# ccg6df_cfp register map
Vendor: Infineon Technologies; Series: CCG6DF_CFP; File version: 1.0
CPU: CM0PLUS r0p1, little endian, MPU, no FPU, VTOR, 2 interrupt priority bits, 20 interrupts
Registers are 32-bit, read-write, reset 0x0 unless marked. A register's access mark holds for its fields unless they carry their own. Offsets are from the block's base; [hi:lo] are bit positions.

## CRYPTOLITE
Base 0x400C0000
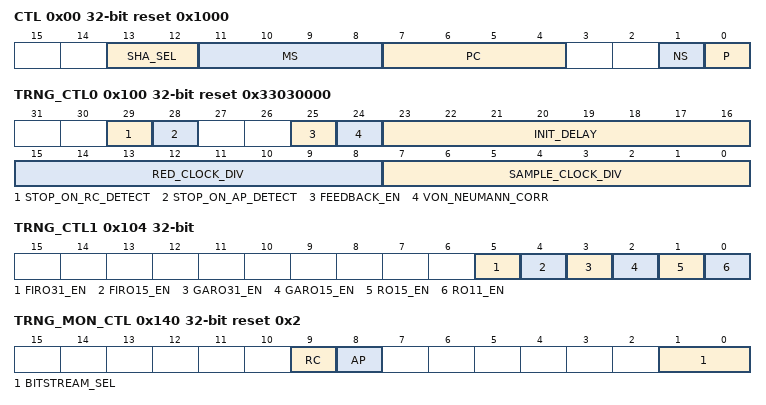
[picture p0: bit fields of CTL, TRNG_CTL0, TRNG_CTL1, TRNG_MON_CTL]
0x00 CTL reset 0x1000 (reset mask 0x3F00) — Control
  [13:12] SHA_SEL — Selects SHA function for use. 0x0: SHA operation is disabled. 0x1: SHA-256 operation is enabled. 0x2: SHA-384 operation is enabled. 0x3: SHA-512 operation is enabled.
  [11:8] MS ro — Master identifier of the cryptography IP. This is a design time configurable parameter.
  [7:4] PC ro — Protection context. This field is set with the protection context of the transaction that writes any (including possible memory holes in the IP aperture) of the CRYPTO component registers; i.e. the context is inherited from the write transaction and not specified by the transaction write data. All CRYPTO component master transactions use the PC field for the protection context.
  [1] NS ro — Secure/on-secure access control: '0': secure. '1': non-secure. This field is set with the secure/non-secure access control of the transaction that writes any (including possible memory holes in the IP aperture) of the CRYPTO component registers; i.e. the access control is inherited from the write transaction and not specified by the transaction write data. All CRYPTO component master transactions use the NS field for the secure/non-secure access control ('hprot[4]').
  [0] P ro — User/privileged access control: '0': user mode. '1': privileged mode. This field is set with the user/privileged access control of the transaction that writes any (including possible memory holes in the IP aperture) of the CRYPTO component registers; i.e. the access control is inherited from the write transaction and not specified by the transaction write data. All CRYPTO component master transactions use the P field for the user/privileged access control ('hprot[1]').
0x04 STATUS ro
  [0] BUSY — Busy indication: '0': IP not busy. '1': IP busy (AES, SHA or VU functionality (TRNG functionality NOT included)).
0x10 ECC_CTL — ECC control
  [3] CHECK_EN — ECC checking enable: '0': Disabled. No ECC checking, no fault reporting. '1': Enabled. ECC checking is performed for the AHB-Lite master interface incoming read data and for the AHB-Lite slave interface incoming write data (for MMIO writes). For the AHB-Lite master interface, error correction is NOT performed (even NOT for theoratically correctable ECC errors). Therefore, an ECC error is always non-correctable. ECC errors do not generate a bus error. This decision is made as error corection and bus error generation would end up in a critical timing path. For the AHB-Lite slave interface, error correction is performed for correctable ECC errors. An ECC error is either correctable or non-correctable. Two fault signal interfaces are supported for correctable and non-correctable ECC errors.
0x40 AES_DESCR reset not defined — AES descriptor pointer
  [31:2] PTR — AES descriptor pointer. The descriptor points to a structure with 32-bit words: Word 0: Pointer to a 128-bit AES key. Word 1: Pointer to a 128-bit source/plaintext. Word 2: Pointer to a 128-bit destination/ciphertext. A write to this register automatically starts a 128-bit AES encryption in ECB mode. The write ONLY takes effect when the IP is NOT busy (STATUS.BUSY is '0'). The write will be made pending/blocked as long as the IP is busy. Note: the pointers must be 4B aligned. Note: HW updates this field when the AES engine is busy.
0x80 VU_DESCR reset not defined — VU descriptor pointer
  [31:2] PTR — VU descriptor pointer. The descriptor points to a structure with 32-bit words: Word 0: Control word. Specifies operand size in 32-bit word multiples. - WORD[7:0]: Source operand 0 32-bit words (minus 1). - WORD[15:8]: Source operand 1 32-bit words (minus 1). - WORD[24:16]: Destination operand 32-bit words (minus 1). - WORD[31:28]: Opcode. '0': multiplication (MUL), '1': addition (ADD), '2': subtraction (SUB), '3': exclusive or (XOR), '4': binary multiplication (XMUL), '5': logical shift right by 1 (LSR1), '6': logical shift left by 1 (LSL1), '7': logical shift right (LSR), '8': conditional syubtraction (COND_SUB). '9': move (MOV). Word 1: Pointer to source 0. Word 2: Pointer to source 1. Word 3: Pointer to destination. A write to this register automatically starts a VU operation. The write ONLY takes effect when the IP is NOT busy (STATUS.BUSY is '0'). The write will be made pending/blocked as long as the IP is busy. Note: the pointers must be 4B aligned. Note: HW updates this field when the VU engine is busy.
0xC0 SHA_DESCR reset not defined — SHA descriptor pointer
  [31:2] PTR — SHA descriptor pointer. The descriptor points to a structure with 32-bit words: For message schedule function: Word 0: Control word. - WORD0[28]: '0' for message schedule function. Word 1: Pointer to 512 b message chunk (input). Word 2: Pointer to 64 * 32 b word message schedule array (output). For process function: Word 0: Control word. - WORD0[28]: '1' for process function. Word 1: Pointer to 8 * 32 b word current hash value (input) and new hash value (output). Word 2: Pointer to 64 * 32 b word message schedule array (input). A write to this register automatically starts a SHA operation. The write ONLY takes effect when the IP is NOT busy (STATUS.BUSY is '0'). The write will be made pending/blocked as long as the IP is busy. Note: the pointers must be 32-bit word aligned. Note: HW updates this field when the SHA engine is busy. This register is used for SHA-256, SHA-384 and SHA-512 operation.
0xF0 INTR_ERROR — Error interrupt
  [0] BUS_ERROR write-1-clears — AHB-Lite master interface bus error or ECC error. Note that the IP terminates its AES, SHA or VU functionality when it detects an error. Note: The error is sticky. This allows SW to check for an error after a series of operations, rather than checking after every individual operation.
0xF4 INTR_ERROR_SET — Error interrupt set
  [0] BUS_ERROR write-1-sets — Write this field with '1' to set corresponding INTR_ERROR field to '1' (a write of '0' has no effect).
0xF8 INTR_ERROR_MASK — Error interrupt mask
  [0] BUS_ERROR — Mask for corresponding field in INTR_ERROR register.
0xFC INTR_ERROR_MASKED ro — Error interrupt masked
  [0] BUS_ERROR — Logical and of corresponding INTR_ERROR and INTR_ERROR_MASK fields.
0x100 TRNG_CTL0 reset 0x33030000 — TRNG control 0
  [29] STOP_ON_RC_DETECT — Specifies if TRNG functionality is stopped on a repetition count test detection (when HW sets INTR_ERROR.TRNG_RC_DETECT to '1'): '0': Functionality is NOT stopped. '1': Functionality is stopped (TRNG_CTL1 fields are set to '0' by HW). The DAS bitstream is set to '0'.
  [28] STOP_ON_AP_DETECT — Specifies if TRNG functionality is stopped on an adaptive proportion test detection (when HW sets INTR_ERROR.TRNG_AP_DETECT to '1'): '0': Functionality is NOT stopped. '1': Functionality is stopped (TRNG_CTL1 fields are set to '0' by HW). The DAS bitstream is set to '0'.
  [25] FEEDBACK_EN — Specifies if the feedback of the reducution state is enabled: '0': Disabled. '1': Enabled. Note: This field is added in the 'mxcryptolite' IP to address CDT#337111, in which it was observed that the reduction state feedback reduces the effectiveness of the 'von Neumann corrector'. The default value is '1' to provide backward compatibility.
  [24] VON_NEUMANN_CORR — Specifies if the 'von Neumann corrector' is disabled or enabled: '0': disabled. '1': enabled. The 'von Neumann corrector' post-processes the reduced bits to remove a '0' or '1' bias. The corrector operates on reduced bit pairs ('oldest bit, newest bit'): '00': no bit is produced. '01': '0' bit is produced (oldest bit). '10': '1' bit is produced (oldest bit). '11': no bit is produced. Note that the corrector produces bits at a random pace and at a frequency that is 1/4 of the reduced bit frequency (reduced bits are processed in pairs, and half of the pairs do NOT produce a bit).
  [23:16] INIT_DELAY — Specifies an initialization delay: number of removed/dropped samples before reduced bits are generated. This field should be programmed in the range [1, 255]. After starting the oscillators, at least the first 2 samples should be removed/dropped to clear the state of internal synchronizers. In addition, it is advised to drop at least the second 2 samples from the oscillators (to circumvent the semi-predictable oscillator startup behavior). This result in the default field value of '3'. Field encoding is as follows: '0': 1 sample is dropped. '1': 2 samples are dropped. ... '255': 256 samples are dropped. The INTR.INITIALIZED interrupt cause is set to '1', when the initialization delay is passed.
  [15:8] RED_CLOCK_DIV — Specifies the clock divider that is used to produce reduced bits. '0': 1 reduced bit is produced for each sample. '1': 1 reduced bit is produced for each 2 samples. ... '255': 1 reduced bit is produced for each 256 samples. The reduced bits are considered random bits and shifted into TRNG_RESULT.DATA.
  [7:0] SAMPLE_CLOCK_DIV — Specifies the clock divider that is used to sample oscillator data. This clock divider is wrt. The IP clock. '0': sample clock is the IP clock. '1': sample clock is the IP clock divided by 2. ... '255': sample clock is the IP clock divided by 256.
0x104 TRNG_CTL1 — TRNG control 1
  [5] FIRO31_EN — FW sets this field to '1' to enable the programmable Fibonacci ring oscillator with up to 31 inverters. The TRNG_FIRO_CTL register specifies the programmable polynomial.
  [4] FIRO15_EN — FW sets this field to '1' to enable the fixed Fibonacci ring oscillator with 15 inverters.
  [3] GARO31_EN — FW sets this field to '1' to enable the programmable Galois ring oscillator with up to 31 inverters. The TRNG_GARO_CTL register specifies the programmable polynomial.
  [2] GARO15_EN — FW sets this field to '1' to enable the fixed Galois ring oscillator with 15 inverters.
  [1] RO15_EN — FW sets this field to '1' to enable the ring oscillator with 15 inverters.
  [0] RO11_EN — FW sets this field to '1' to enable the ring oscillator with 11 inverters.
0x10C TRNG_STATUS ro
  [0] INITIALIZED — Reflects the state of the true random number generator: '0': Not initialized (TRNG_CTL0.INIT_DELAY has NOT passed). '1': Initialized (TRNG_CTL0.INIT_DELAY has passed).
0x110 TRNG_RESULT ro reset not defined
  [31:0] DATA — Generated 32-bit true random number. The INTR.DATA_AVAILABLE interrupt cause is activated when the number is generated.
0x120 TRNG_GARO_CTL reset 0x21F81910 — TRNG GARO control
  [30:0] POLYNOMIAL — Polynomial for programmable Galois ring oscillator. The polynomial is represented WITHOUT the high order bit (this bit is always assumed '1'). The polynomial should be aligned such that the more significant bits (bit 30 and down) contain the polynomial and the less significant bits (bit 0 and up) contain padding '0's. Note: Default value per GESC#113.
0x124 TRNG_FIRO_CTL reset 0x696F0221 — TRNG FIRO control
  [30:0] POLYNOMIAL — Polynomial for programmable Fibonacci ring oscillator. The polynomial is represented WITHOUT the high order bit (this bit is always assumed '1'). The polynomial should be aligned such that the more significant bits (bit 30 and down) contain the polynomial and the less significant bits (bit 0 and up) contain padding '0's. Note: Default value per GESC#113.
0x140 TRNG_MON_CTL reset 0x2 — TRNG monitor control
  [9] RC — Repetition count (RC) test enable: '0': Disabled. '1': Enabled. On a RC detection, HW sets this field to '0' and sets INTR_ERROR.TRNG_RC_DETECT to '1.
  [8] AP — Adaptive proportion (AP) test enable: '0': Disabled. '1': Enabled. On a AP detection, HW sets this field to '0' and sets INTR_ERROR.TRNG_AP_DETECT to '1.
  [1:0] BITSTREAM_SEL — Selection of the bitstream: '0': DAS bitstream. '1': RED bitstream. '2': TR bitstream. '3': Undefined.
0x150 TRNG_MON_RC_CTL reset 0xFF — TRNG monitor RC control
  [7:0] CUTOFF_COUNT8 — Cutoff count (legal range is [1, 255]): '0': Illegal. '1': 1 repetition. ... '255': 255 repetitions.
0x158 TRNG_MON_RC_STATUS0 ro — TRNG monitor RC status 0
  [0] BIT — Current active bit value: '0': '0'. '1': '1'. This field is only valid when TRNG_MON_RC_STATUS1.REP_COUNT is NOT equal to '0'.
0x15C TRNG_MON_RC_STATUS1 ro — TRNG monitor RC status 1
  [7:0] REP_COUNT — Number of repetitions of the current active bit counter: '0': 0 repetitions. ... '255': 255 repetitions.
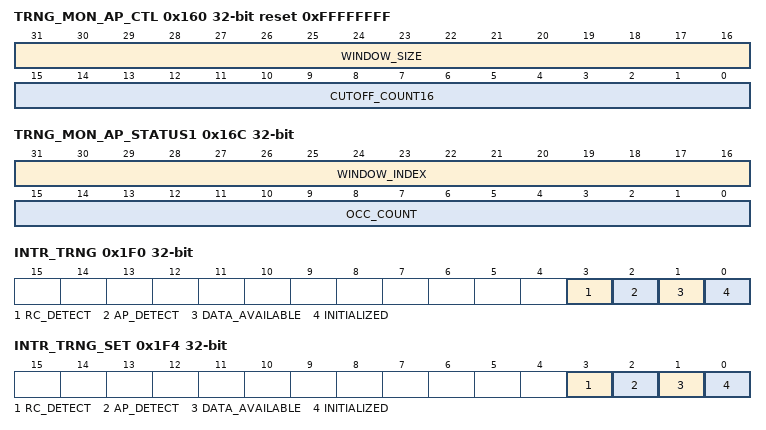
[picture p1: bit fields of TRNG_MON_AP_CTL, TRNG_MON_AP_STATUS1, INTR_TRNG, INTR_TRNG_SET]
0x160 TRNG_MON_AP_CTL reset 0xFFFFFFFF — TRNG monitor AP control
  [31:16] WINDOW_SIZE — Window size (minus 1) : '0': 1 bit. ... '65535': 65536 bits.
  [15:0] CUTOFF_COUNT16 — Cutoff count (legal range is [1, 65535]). '0': Illegal. '1': 1 occurrence. ... '65535': 65535 occurrences.
0x168 TRNG_MON_AP_STATUS0 ro — TRNG monitor AP status 0
  [0] BIT — Current active bit value: '0': '0'. '1': '1'. This field is only valid when TRNG_MON_AP_STATUS1.OCC_COUNT is NOT equal to '0'.
0x16C TRNG_MON_AP_STATUS1 ro — TRNG monitor AP status 1
  [31:16] WINDOW_INDEX — Counter to keep track of the current index in the window (counts from '0' to TRNG_MON_AP_CTL.WINDOW_SIZE to '0').
  [15:0] OCC_COUNT — Number of occurrences of the current active bit counter: '0': 0 occurrences ... '65535': 65535 occurrences
0x1F0 INTR_TRNG — TRNG interrupt
  [3] RC_DETECT write-1-clears — This interrupt cause is activated (HW sets the field to '1') when the TRNG monitor detects an 'repetition count' error.
  [2] AP_DETECT write-1-clears — This interrupt cause is activated (HW sets the field to '1') when the TRNG monitor detects an 'adaptive proportion' error.
  [1] DATA_AVAILABLE write-1-clears — This interrupt cause is activated (HW sets the field to '1') when 32 bits of TRNG data becomes available in TRNG_RESULT.
  [0] INITIALIZED write-1-clears — This interrupt cause is activated (HW sets the field to '1') when the TRNG is initialized.
0x1F4 INTR_TRNG_SET — TRNG Interrupt set
  [3] RC_DETECT write-1-sets — SW writes a '1' to this field to set the corresponding field in interrupt request register.
  [2] AP_DETECT write-1-sets — SW writes a '1' to this field to set the corresponding field in interrupt request register.
  [1] DATA_AVAILABLE write-1-sets — SW writes a '1' to this field to set the corresponding field in interrupt request register.
  [0] INITIALIZED write-1-sets — SW writes a '1' to this field to set the corresponding field in interrupt request register.
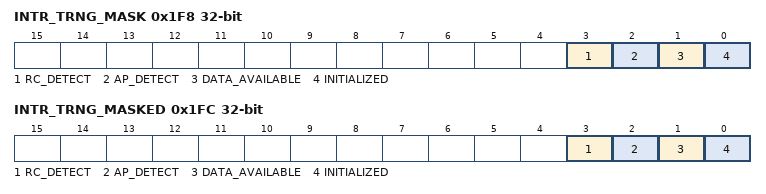
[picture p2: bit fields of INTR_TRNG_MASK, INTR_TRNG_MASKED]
0x1F8 INTR_TRNG_MASK — TRNG Interrupt mask
  [3] RC_DETECT — Mask bit for corresponding field in interrupt request register.
  [2] AP_DETECT — Mask bit for corresponding field in interrupt request register.
  [1] DATA_AVAILABLE — Mask bit for corresponding field in interrupt request register.
  [0] INITIALIZED — Mask bit for corresponding field in interrupt request register.
0x1FC INTR_TRNG_MASKED ro — TRNG Interrupt masked
  [3] RC_DETECT — Logical and of corresponding request and mask bits.
  [2] AP_DETECT — Logical and of corresponding request and mask bits.
  [1] DATA_AVAILABLE — Logical and of corresponding request and mask bits.
  [0] INITIALIZED — Logical and of corresponding request and mask bits.

## Notices in the file
(c) 2016-2026, Infineon Technologies AG or an affiliate of
Infineon Technologies AG.
SPDX-License-Identifier: Apache-2.0
Licensed under the Apache License, Version 2.0 (the "License");
you may not use this file except in compliance with the License.
You may obtain a copy of the License at
http://www.apache.org/licenses/LICENSE-2.0
Unless required by applicable law or agreed to in writing, software
distributed under the License is distributed on an "AS IS" BASIS,
WITHOUT WARRANTIES OR CONDITIONS OF ANY KIND, either express or implied.
See the License for the specific language governing permissions and
limitations under the License.
